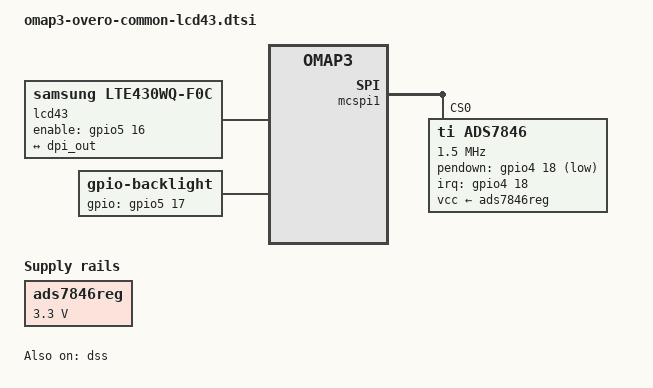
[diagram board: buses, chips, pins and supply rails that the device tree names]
&omap3_pmx_core {
	dss_dpi_pins: dss-dpi-pins {
		pinctrl-single,pins = <
			OMAP3_CORE1_IOPAD(0x20d4, PIN_OUTPUT | MUX_MODE0)	 
			OMAP3_CORE1_IOPAD(0x20d6, PIN_OUTPUT | MUX_MODE0)	 
			OMAP3_CORE1_IOPAD(0x20d8, PIN_OUTPUT | MUX_MODE0)	 
			OMAP3_CORE1_IOPAD(0x20da, PIN_OUTPUT | MUX_MODE0)	 
			OMAP3_CORE1_IOPAD(0x20dc, PIN_OUTPUT | MUX_MODE0)	 
			OMAP3_CORE1_IOPAD(0x20de, PIN_OUTPUT | MUX_MODE0)	 
			OMAP3_CORE1_IOPAD(0x20e0, PIN_OUTPUT | MUX_MODE0)	 
			OMAP3_CORE1_IOPAD(0x20e2, PIN_OUTPUT | MUX_MODE0)	 
			OMAP3_CORE1_IOPAD(0x20e4, PIN_OUTPUT | MUX_MODE0)	 
			OMAP3_CORE1_IOPAD(0x20e6, PIN_OUTPUT | MUX_MODE0)	 
			OMAP3_CORE1_IOPAD(0x20e8, PIN_OUTPUT | MUX_MODE0)	 
			OMAP3_CORE1_IOPAD(0x20ea, PIN_OUTPUT | MUX_MODE0)	 
			OMAP3_CORE1_IOPAD(0x20ec, PIN_OUTPUT | MUX_MODE0)	 
			OMAP3_CORE1_IOPAD(0x20ee, PIN_OUTPUT | MUX_MODE0)	 
			OMAP3_CORE1_IOPAD(0x20f0, PIN_OUTPUT | MUX_MODE0)	 
			OMAP3_CORE1_IOPAD(0x20f2, PIN_OUTPUT | MUX_MODE0)	 
			OMAP3_CORE1_IOPAD(0x20f4, PIN_OUTPUT | MUX_MODE0)	 
			OMAP3_CORE1_IOPAD(0x20f6, PIN_OUTPUT | MUX_MODE0)	 
			OMAP3_CORE1_IOPAD(0x20f8, PIN_OUTPUT | MUX_MODE0)	 
			OMAP3_CORE1_IOPAD(0x20fa, PIN_OUTPUT | MUX_MODE0)	 
			OMAP3_CORE1_IOPAD(0x20fc, PIN_OUTPUT | MUX_MODE0)	 
			OMAP3_CORE1_IOPAD(0x20fe, PIN_OUTPUT | MUX_MODE0)	 
			OMAP3_CORE1_IOPAD(0x2100, PIN_OUTPUT | MUX_MODE0)	 
			OMAP3_CORE1_IOPAD(0x2102, PIN_OUTPUT | MUX_MODE0)	 
			OMAP3_CORE1_IOPAD(0x2104, PIN_OUTPUT | MUX_MODE0)	 
			OMAP3_CORE1_IOPAD(0x2106, PIN_OUTPUT | MUX_MODE0)	 
			OMAP3_CORE1_IOPAD(0x2108, PIN_OUTPUT | MUX_MODE0)	 
			OMAP3_CORE1_IOPAD(0x210a, PIN_OUTPUT | MUX_MODE0)	 
		>;
	};
	lte430_pins: lte430-pins {
		pinctrl-single,pins = <
			OMAP3_CORE1_IOPAD(0x2174, PIN_OUTPUT | MUX_MODE4)	 
		>;
	};
	backlight_pins: backlight-pins {
		pinctrl-single,pins = <
			OMAP3_CORE1_IOPAD(0x2176, PIN_OUTPUT | MUX_MODE4)	 
		>;
	};
	mcspi1_pins: mcspi1-pins {
		pinctrl-single,pins = <
			OMAP3_CORE1_IOPAD(0x21c8, PIN_INPUT | MUX_MODE0)	 
			OMAP3_CORE1_IOPAD(0x21ca, PIN_INPUT | MUX_MODE0)	 
			OMAP3_CORE1_IOPAD(0x21cc, PIN_INPUT | MUX_MODE0)	 
			OMAP3_CORE1_IOPAD(0x21ce, PIN_INPUT | MUX_MODE0)	 
		>;
	};
	ads7846_pins: ads7846-pins {
		pinctrl-single,pins = <
			OMAP3_CORE1_IOPAD(0x2138, PIN_INPUT_PULLDOWN | MUX_MODE4)	 
		>;
	};
};
&vpll2 {
	regulator-always-on;
};
&dss {
	status = "okay";
	pinctrl-names = "default";
	pinctrl-0 = <&dss_dpi_pins>;
	port {
		dpi_out: endpoint {
			remote-endpoint = <&lcd_in>;
			data-lines = <24>;
		};
	};
};
/ {
	aliases {
		display0 = &lcd0;
	};
	lcd0: display {
		compatible = "samsung,lte430wq-f0c", "panel-dpi";
		label = "lcd43";
		pinctrl-names = "default";
		pinctrl-0 = <&lte430_pins>;
		enable-gpios = <&gpio5 16 GPIO_ACTIVE_HIGH>;		 
		port {
			lcd_in: endpoint {
				remote-endpoint = <&dpi_out>;
			};
		};
		panel-timing {
			clock-frequency = <9200000>;
			hactive = <480>;
			vactive = <272>;
			hfront-porch = <8>;
			hback-porch = <4>;
			hsync-len = <41>;
			vback-porch = <2>;
			vfront-porch = <4>;
			vsync-len = <10>;
			hsync-active = <0>;
			vsync-active = <0>;
			de-active = <1>;
			pixelclk-active = <1>;
		};
	};
	ads7846reg: ads7846-reg {
		compatible = "regulator-fixed";
		regulator-name = "ads7846-reg";
		regulator-min-microvolt = <3300000>;
		regulator-max-microvolt = <3300000>;
	};
	backlight {
		compatible = "gpio-backlight";
		pinctrl-names = "default";
		pinctrl-0 = <&backlight_pins>;
		gpios = <&gpio5 17 GPIO_ACTIVE_HIGH>;		 
		default-on;
	};
};
&mcspi1 {
	pinctrl-names = "default";
	pinctrl-0 = <&mcspi1_pins>;
	ads7846@0 {
		pinctrl-names = "default";
		pinctrl-0 = <&ads7846_pins>;
		compatible = "ti,ads7846";
		vcc-supply = <&ads7846reg>;
		reg = <0>;				 
		spi-max-frequency = <1500000>;
		interrupt-parent = <&gpio4>;
		interrupts = <18 0>;			 
		pendown-gpio = <&gpio4 18 GPIO_ACTIVE_LOW>;
		ti,x-min = /bits/ 16 <0x0>;
		ti,x-max = /bits/ 16 <0x0fff>;
		ti,y-min = /bits/ 16 <0x0>;
		ti,y-max = /bits/ 16 <0x0fff>;
		ti,x-plate-ohms = /bits/ 16 <180>;
		ti,pressure-max = /bits/ 16 <255>;
		wakeup-source;
	};
};
